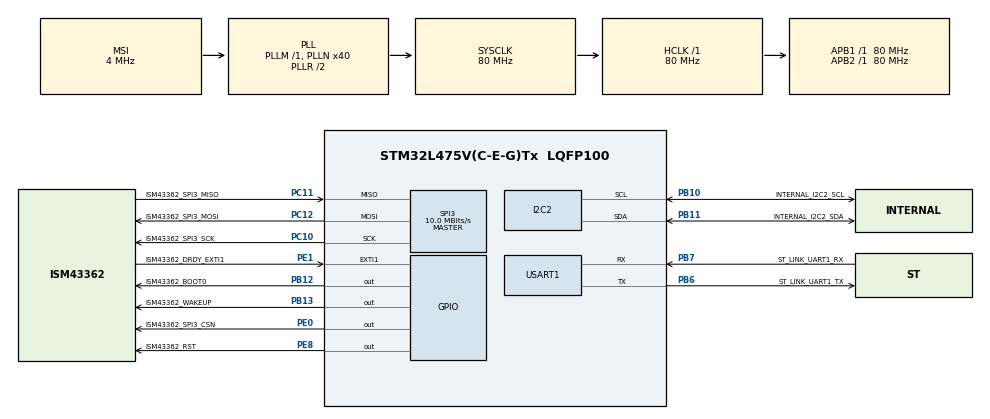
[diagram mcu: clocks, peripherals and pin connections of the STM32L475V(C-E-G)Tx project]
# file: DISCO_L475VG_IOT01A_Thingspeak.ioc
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FREERTOS.Tasks01=defaultTask,24,128,StartDefaultTask,Default,NULL,Static,defaultTaskBuffer,defaultTaskControlBlock
FREERTOS.configCHECK_FOR_STACK_OVERFLOW=2
FREERTOS.configTOTAL_HEAP_SIZE=1024
FREERTOS.configUSE_NEWLIB_REENTRANT=1
I2C2.Timing=0x10909CEC
Mcu.Family=STM32L4
Mcu.Name=STM32L475V(C-E-G)Tx
Mcu.Package=LQFP100
NVIC.PriorityGroup=NVIC_PRIORITYGROUP_4
NVIC.TIM6_DAC_IRQn=true\:15\:0\:false\:false\:true\:false\:false\:true\:true
NVIC.TimeBase=TIM6_DAC_IRQn
NVIC.TimeBaseIP=TIM6
PA13\ (JTMS-SWDIO).GPIO_Label=SYS_JTMS_SWDIO
PA13\ (JTMS-SWDIO).Mode=Serial_Wire
PA13\ (JTMS-SWDIO).Signal=SYS_JTMS-SWDIO
PA14\ (JTCK-SWCLK).GPIO_Label=SYS_JTCK_SWCLK
PA14\ (JTCK-SWCLK).Mode=Serial_Wire
PA14\ (JTCK-SWCLK).Signal=SYS_JTCK-SWCLK
PB10.GPIO_Label=INTERNAL_I2C2_SCL
PB10.GPIO_Pu=GPIO_PULLUP
PB10.Mode=I2C
PB10.Signal=I2C2_SCL
PB11.GPIO_Label=INTERNAL_I2C2_SDA
PB11.GPIO_Pu=GPIO_PULLUP
PB11.Mode=I2C
PB11.Signal=I2C2_SDA
PB12.GPIO_Label=ISM43362_BOOT0
PB12.Signal=GPIO_Output
PB13.GPIO_Label=ISM43362_WAKEUP
PB13.Signal=GPIO_Output
PB6.GPIO_Label=ST_LINK_UART1_TX
PB6.Mode=Asynchronous
PB6.Signal=USART1_TX
PB7.GPIO_Label=ST_LINK_UART1_RX
PB7.Mode=Asynchronous
PB7.Signal=USART1_RX
PC10.GPIO_Label=ISM43362_SPI3_SCK
PC10.GPIO_Speed=GPIO_SPEED_FREQ_MEDIUM
PC10.Mode=Full_Duplex_Master
PC10.Signal=SPI3_SCK
PC11.GPIO_Label=ISM43362_SPI3_MISO
PC11.GPIO_PuPd=GPIO_PULLUP
PC11.GPIO_Speed=GPIO_SPEED_FREQ_MEDIUM
PC11.Mode=Full_Duplex_Master
PC11.Signal=SPI3_MISO
PC12.GPIO_Label=ISM43362_SPI3_MOSI
PC12.GPIO_Speed=GPIO_SPEED_FREQ_MEDIUM
PC12.Mode=Full_Duplex_Master
PC12.Signal=SPI3_MOSI
PE0.GPIO_Label=ISM43362_SPI3_CSN
PE0.GPIO_Speed=GPIO_SPEED_FREQ_MEDIUM
PE0.PinState=GPIO_PIN_SET
PE0.Signal=GPIO_Output
PE1.GPIO_Label=ISM43362_DRDY_EXTI1
PE1.GPIO_ModeDefaultEXTI=GPIO_MODE_IT_RISING
PE1.Signal=GPXTI1
PE8.GPIO_Label=ISM43362_RST
PE8.Signal=GPIO_Output
ProjectManager.HeapSize=0x200
ProjectManager.StackSize=0x400
ProjectManager.TargetToolchain=STM32CubeIDE
RCC.ADCFreq_Value=48000000
RCC.AHBFreq_Value=80000000
RCC.APB1Freq_Value=80000000
RCC.APB1TimFreq_Value=80000000
RCC.APB2Freq_Value=80000000
RCC.APB2TimFreq_Value=80000000
RCC.CortexFreq_Value=80000000
RCC.HCLKFreq_Value=80000000
RCC.HSE_VALUE=8000000
RCC.HSI_VALUE=16000000
RCC.LSE_VALUE=32768
RCC.MSI_VALUE=4000000
RCC.PLLN=40
RCC.PLLSAI1N=24
RCC.SYSCLKFreq_VALUE=80000000
RCC.SYSCLKSource=RCC_SYSCLKSOURCE_PLLCLK
RCC.USBFreq_Value=48000000
RCC.VCOOutputFreq_Value=160000000
SPI3.BaudRatePrescaler=SPI_BAUDRATEPRESCALER_8
SPI3.CalculateBaudRate=10.0 MBits/s
SPI3.DataSize=SPI_DATASIZE_16BIT
SPI3.Direction=SPI_DIRECTION_2LINES
SPI3.Mode=SPI_MODE_MASTER
SPI3.NSSPMode=SPI_NSS_PULSE_DISABLE
SPI3.VirtualType=VM_MASTER
USART1.VirtualMode-Asynchronous=VM_ASYNC
VP_FREERTOS_VS_CMSIS_V2.Mode=CMSIS_V2
VP_SYS_VS_tim6.Mode=TIM6
board=custom

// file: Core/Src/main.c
/* USER CODE BEGIN Header */
/**
  ******************************************************************************
  * @file           : main.c
  * @brief          : Main program body
  ******************************************************************************
  * @attention
  *
  * Copyright (c) 2026 STMicroelectronics.
  * All rights reserved.
  *
  * This software is licensed under terms that can be found in the LICENSE file
  * in the root directory of this software component.
  * If no LICENSE file comes with this software, it is provided AS-IS.
  *
  ******************************************************************************
  */
/* USER CODE END Header */
#include "main.h"
#include "cmsis_os.h"

/* USER CODE BEGIN Includes */
#include <stdio.h>
#include "app.h"
#include "reset_info.h"
/* USER CODE END Includes */

typedef StaticTask_t osStaticThreadDef_t;

I2C_HandleTypeDef hi2c2;

SPI_HandleTypeDef hspi3;

UART_HandleTypeDef huart1;

/* Definitions for defaultTask */
osThreadId_t defaultTaskHandle;
uint32_t defaultTaskBuffer[ 128 ];
osStaticThreadDef_t defaultTaskControlBlock;
const osThreadAttr_t defaultTask_attributes = {
  .name = "defaultTask",
  .cb_mem = &defaultTaskControlBlock,
  .cb_size = sizeof(defaultTaskControlBlock),
  .stack_mem = &defaultTaskBuffer[0],
  .stack_size = sizeof(defaultTaskBuffer),
  .priority = (osPriority_t) osPriorityNormal,
};

void SystemClock_Config(void);
static void MX_GPIO_Init(void);
static void MX_I2C2_Init(void);
static void MX_SPI3_Init(void);
static void MX_USART1_UART_Init(void);
void StartDefaultTask(void *argument);

int main(void)
{

  /* USER CODE BEGIN 1 */
  /* Reset cause and Wi-Fi restart counter, before anything else touches the RCC (Core/Src/reset_info.c). */
  reset_info_capture();
  /* USER CODE END 1 */

  /* MCU Configuration--------------------------------------------------------*/

  /* Reset of all peripherals, Initializes the Flash interface and the Systick. */
  HAL_Init();

  /* Configure the system clock */
  SystemClock_Config();

  /* Initialize all configured peripherals */
  MX_GPIO_Init();
  MX_I2C2_Init();
  MX_SPI3_Init();
  MX_USART1_UART_Init();
  /* USER CODE BEGIN 2 */
  /* Unbuffered stdout: newlib would otherwise malloc() a 1 KB buffer on the first printf().
     printf() output goes to USART1 (Core/Src/console_io.c). */
  setvbuf(stdout, NULL, _IONBF, 0);
  /* USER CODE END 2 */

  /* Init scheduler */
  osKernelInitialize();

  /* Create the thread(s) */
  /* creation of defaultTask */
  defaultTaskHandle = osThreadNew(StartDefaultTask, NULL, &defaultTask_attributes);

  /* USER CODE BEGIN RTOS_THREADS */
  /* The CSP application: a static MainApp thread that starts the process network (Core/Src/app.cpp). */
  csp_app_main_init();
  /* USER CODE END RTOS_THREADS */

  /* Start scheduler */
  osKernelStart();

  /* We should never get here as control is now taken by the scheduler */

  /* Infinite loop */
  while (1)
  {

  }
}

void SystemClock_Config(void)
{
  RCC_OscInitTypeDef RCC_OscInitStruct = {0};
  RCC_ClkInitTypeDef RCC_ClkInitStruct = {0};

  /** Configure the main internal regulator output voltage
  */
  if (HAL_PWREx_ControlVoltageScaling(PWR_REGULATOR_VOLTAGE_SCALE1) != HAL_OK)
  {
    Error_Handler();
  }

  /** Initializes the RCC Oscillators according to the specified parameters
  * in the RCC_OscInitTypeDef structure.
  */
  RCC_OscInitStruct.OscillatorType = RCC_OSCILLATORTYPE_MSI;
  RCC_OscInitStruct.MSIState = RCC_MSI_ON;
  RCC_OscInitStruct.MSICalibrationValue = 0;
  RCC_OscInitStruct.MSIClockRange = RCC_MSIRANGE_6;
  RCC_OscInitStruct.PLL.PLLState = RCC_PLL_ON;
  RCC_OscInitStruct.PLL.PLLSource = RCC_PLLSOURCE_MSI;
  RCC_OscInitStruct.PLL.PLLM = 1;
  RCC_OscInitStruct.PLL.PLLN = 40;
  RCC_OscInitStruct.PLL.PLLP = RCC_PLLP_DIV7;
  RCC_OscInitStruct.PLL.PLLQ = RCC_PLLQ_DIV2;
  RCC_OscInitStruct.PLL.PLLR = RCC_PLLR_DIV2;
  if (HAL_RCC_OscConfig(&RCC_OscInitStruct) != HAL_OK)
  {
    Error_Handler();
  }

  /** Initializes the CPU, AHB and APB buses clocks
  */
  RCC_ClkInitStruct.ClockType = RCC_CLOCKTYPE_HCLK|RCC_CLOCKTYPE_SYSCLK
                              |RCC_CLOCKTYPE_PCLK1|RCC_CLOCKTYPE_PCLK2;
  RCC_ClkInitStruct.SYSCLKSource = RCC_SYSCLKSOURCE_PLLCLK;
  RCC_ClkInitStruct.AHBCLKDivider = RCC_SYSCLK_DIV1;
  RCC_ClkInitStruct.APB1CLKDivider = RCC_HCLK_DIV1;
  RCC_ClkInitStruct.APB2CLKDivider = RCC_HCLK_DIV1;

  if (HAL_RCC_ClockConfig(&RCC_ClkInitStruct, FLASH_LATENCY_4) != HAL_OK)
  {
    Error_Handler();
  }
}

static void MX_I2C2_Init(void)
{

  hi2c2.Instance = I2C2;
  hi2c2.Init.Timing = 0x10909CEC;
  hi2c2.Init.OwnAddress1 = 0;
  hi2c2.Init.AddressingMode = I2C_ADDRESSINGMODE_7BIT;
  hi2c2.Init.DualAddressMode = I2C_DUALADDRESS_DISABLE;
  hi2c2.Init.OwnAddress2 = 0;
  hi2c2.Init.OwnAddress2Masks = I2C_OA2_NOMASK;
  hi2c2.Init.GeneralCallMode = I2C_GENERALCALL_DISABLE;
  hi2c2.Init.NoStretchMode = I2C_NOSTRETCH_DISABLE;
  if (HAL_I2C_Init(&hi2c2) != HAL_OK)
  {
    Error_Handler();
  }

  /** Configure Analogue filter
  */
  if (HAL_I2CEx_ConfigAnalogFilter(&hi2c2, I2C_ANALOGFILTER_ENABLE) != HAL_OK)
  {
    Error_Handler();
  }

  /** Configure Digital filter
  */
  if (HAL_I2CEx_ConfigDigitalFilter(&hi2c2, 0) != HAL_OK)
  {
    Error_Handler();
  }

}

static void MX_SPI3_Init(void)
{

  /* SPI3 parameter configuration*/
  hspi3.Instance = SPI3;
  hspi3.Init.Mode = SPI_MODE_MASTER;
  hspi3.Init.Direction = SPI_DIRECTION_2LINES;
  hspi3.Init.DataSize = SPI_DATASIZE_16BIT;
  hspi3.Init.CLKPolarity = SPI_POLARITY_LOW;
  hspi3.Init.CLKPhase = SPI_PHASE_1EDGE;
  hspi3.Init.NSS = SPI_NSS_SOFT;
  hspi3.Init.BaudRatePrescaler = SPI_BAUDRATEPRESCALER_8;
  hspi3.Init.FirstBit = SPI_FIRSTBIT_MSB;
  hspi3.Init.TIMode = SPI_TIMODE_DISABLE;
  hspi3.Init.CRCCalculation = SPI_CRCCALCULATION_DISABLE;
  hspi3.Init.CRCPolynomial = 7;
  hspi3.Init.CRCLength = SPI_CRC_LENGTH_DATASIZE;
  hspi3.Init.NSSPMode = SPI_NSS_PULSE_DISABLE;
  if (HAL_SPI_Init(&hspi3) != HAL_OK)
  {
    Error_Handler();
  }

}

static void MX_USART1_UART_Init(void)
{

  huart1.Instance = USART1;
  huart1.Init.BaudRate = 115200;
  huart1.Init.WordLength = UART_WORDLENGTH_8B;
  huart1.Init.StopBits = UART_STOPBITS_1;
  huart1.Init.Parity = UART_PARITY_NONE;
  huart1.Init.Mode = UART_MODE_TX_RX;
  huart1.Init.HwFlowCtl = UART_HWCONTROL_NONE;
  huart1.Init.OverSampling = UART_OVERSAMPLING_16;
  huart1.Init.OneBitSampling = UART_ONE_BIT_SAMPLE_DISABLE;
  huart1.AdvancedInit.AdvFeatureInit = UART_ADVFEATURE_NO_INIT;
  if (HAL_UART_Init(&huart1) != HAL_OK)
  {
    Error_Handler();
  }

}

static void MX_GPIO_Init(void)
{
  GPIO_InitTypeDef GPIO_InitStruct = {0};

  /* GPIO Ports Clock Enable */
  __HAL_RCC_GPIOE_CLK_ENABLE();
  __HAL_RCC_GPIOB_CLK_ENABLE();
  __HAL_RCC_GPIOA_CLK_ENABLE();
  __HAL_RCC_GPIOC_CLK_ENABLE();

  /*Configure GPIO pin Output Level */
  HAL_GPIO_WritePin(ISM43362_RST_GPIO_Port, ISM43362_RST_Pin, GPIO_PIN_RESET);

  /*Configure GPIO pin Output Level */
  HAL_GPIO_WritePin(GPIOB, ISM43362_BOOT0_Pin|ISM43362_WAKEUP_Pin, GPIO_PIN_RESET);

  /*Configure GPIO pin Output Level */
  HAL_GPIO_WritePin(ISM43362_SPI3_CSN_GPIO_Port, ISM43362_SPI3_CSN_Pin, GPIO_PIN_SET);

  /*Configure GPIO pin : ISM43362_RST_Pin */
  GPIO_InitStruct.Pin = ISM43362_RST_Pin;
  GPIO_InitStruct.Mode = GPIO_MODE_OUTPUT_PP;
  GPIO_InitStruct.Pull = GPIO_NOPULL;
  GPIO_InitStruct.Speed = GPIO_SPEED_FREQ_LOW;
  HAL_GPIO_Init(ISM43362_RST_GPIO_Port, &GPIO_InitStruct);

  /*Configure GPIO pins : ISM43362_BOOT0_Pin ISM43362_WAKEUP_Pin */
  GPIO_InitStruct.Pin = ISM43362_BOOT0_Pin|ISM43362_WAKEUP_Pin;
  GPIO_InitStruct.Mode = GPIO_MODE_OUTPUT_PP;
  GPIO_InitStruct.Pull = GPIO_NOPULL;
  GPIO_InitStruct.Speed = GPIO_SPEED_FREQ_LOW;
  HAL_GPIO_Init(GPIOB, &GPIO_InitStruct);

  /*Configure GPIO pin : ISM43362_SPI3_CSN_Pin */
  GPIO_InitStruct.Pin = ISM43362_SPI3_CSN_Pin;
  GPIO_InitStruct.Mode = GPIO_MODE_OUTPUT_PP;
  GPIO_InitStruct.Pull = GPIO_NOPULL;
  GPIO_InitStruct.Speed = GPIO_SPEED_FREQ_MEDIUM;
  HAL_GPIO_Init(ISM43362_SPI3_CSN_GPIO_Port, &GPIO_InitStruct);

  /*Configure GPIO pin : ISM43362_DRDY_EXTI1_Pin */
  GPIO_InitStruct.Pin = ISM43362_DRDY_EXTI1_Pin;
  GPIO_InitStruct.Mode = GPIO_MODE_IT_RISING;
  GPIO_InitStruct.Pull = GPIO_NOPULL;
  HAL_GPIO_Init(ISM43362_DRDY_EXTI1_GPIO_Port, &GPIO_InitStruct);

}

void StartDefaultTask(void *argument)
{
  /* USER CODE BEGIN 5 */
  /* Not used: STM32CubeMX always generates this thread. The application runs in the
     MainApp thread and the processes it starts (Core/Src/app.cpp). */
  osThreadExit();
  /* USER CODE END 5 */
}

void HAL_TIM_PeriodElapsedCallback(TIM_HandleTypeDef *htim)
{
  if (htim->Instance == TIM6)
  {
    HAL_IncTick();
  }
}

void Error_Handler(void)
{
  __disable_irq();
  while (1)
  {
  }
}

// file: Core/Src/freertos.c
/* USER CODE BEGIN Header */
/**
  ******************************************************************************
  * File Name          : freertos.c
  * Description        : Code for freertos applications
  ******************************************************************************
  * @attention
  *
  * Copyright (c) 2026 STMicroelectronics.
  * All rights reserved.
  *
  * This software is licensed under terms that can be found in the LICENSE file
  * in the root directory of this software component.
  * If no LICENSE file comes with this software, it is provided AS-IS.
  *
  ******************************************************************************
  */
/* USER CODE END Header */

#include "FreeRTOS.h"
#include "task.h"
#include "main.h"

/* Hook prototypes */
void vApplicationStackOverflowHook(xTaskHandle xTask, signed char *pcTaskName);

/* USER CODE BEGIN 4 */
void app_stack_overflow(const char *task_name);   /* Core/Src/console_io.c */

/* configCHECK_FOR_STACK_OVERFLOW = 2: FreeRTOS checks a thread's stack at every context
   switch and calls this hook if the stack pointer went past the end or the last 16 bytes
   were overwritten. Prints the thread's name and halts. */
void vApplicationStackOverflowHook(xTaskHandle xTask, signed char *pcTaskName)
{
  (void)xTask;
  app_stack_overflow((const char *)pcTaskName);
}
/* USER CODE END 4 */
